# PT32x066xx register map
File version: 0.3
Registers are 32-bit, read-write, reset 0x0 unless marked. A register's access mark holds for its fields unless they carry their own. Offsets are from the block's base; [hi:lo] are bit positions.

## SDADC0 — Segma Delta Analog-to-digital converters
Base 0x40012000
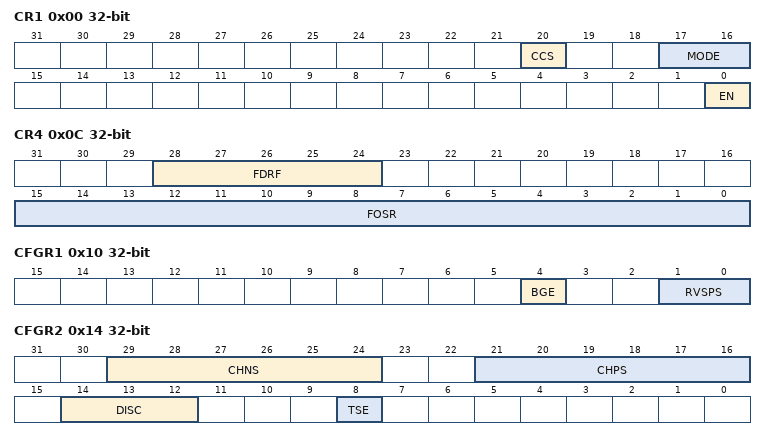
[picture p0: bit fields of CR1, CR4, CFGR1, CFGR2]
0x00 CR1 — Control Register 1
  [20] CCS — Chopper clock source selection
  [17:16] MODE — Working mode
  [0] EN — ADC enable
0x04 CR2 — Control Register 2
  [2] DMAE — SDADC DMA enable
0x0C CR4 — Control Register 4
  [28:24] FDRF — CIC filter data maximum output resolution factor
  [15:0] FOSR — CIC filter oversampling ratio
0x10 CFGR1 — Configuration Register 1
  [4] BGE — BGREF enable
  [1:0] RVSPS — Reference voltage source positive selection
0x14 CFGR2 — Configuration Register 2
  [29:24] CHNS — SDADC channel negative selection
  [21:16] CHPS — SDADC channel positive selection
  [14:12] DISC — Number of conversions to be Discarded
  [8] TSE — Temperature sensor enable
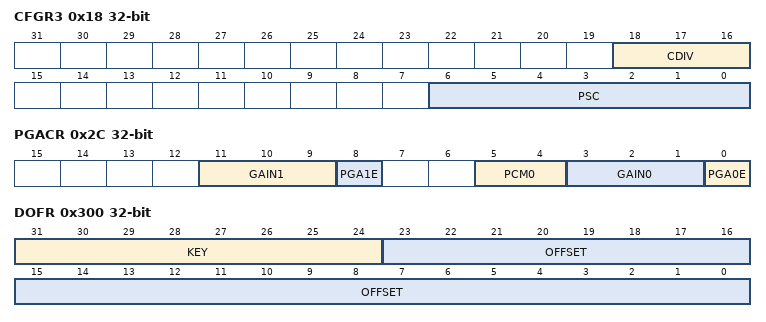
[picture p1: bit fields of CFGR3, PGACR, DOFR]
0x18 CFGR3 — Configuration Register 3
  [18:16] CDIV — Chopper clock divider
  [6:0] PSC — SADC prescaler
0x1C IER — Interrupt Enable Register
  [1] EOCIE — Regular channel end of conversion interrupt enable
0x20 SR ro — Status Register
  [1] EOC — Regular channel end of conversion flag
0x2C PGACR — PGA Control Register
  [11:9] GAIN1 — PGA1 gain value selection
  [8] PGA1E — PGA1 enable
  [5:4] PCM0 — PGA0 chopper working mode selection
  [3:1] GAIN0 — PGA0 gain value selection
  [0] PGA0E — PGA0 enable
0x30 DR ro — Data Register
  [23:0] DATA — SDADC data
0x300 DOFR — Data Offset Register
  [31:24] KEY — Key value
  [23:0] OFFSET — SDADC data offset value
0x304 CCR1 — Common Control Register 1
  [1:0] CHOPE — SDADC chopper enable

## LPTIM — Low Power timer
Base 0x40006C00
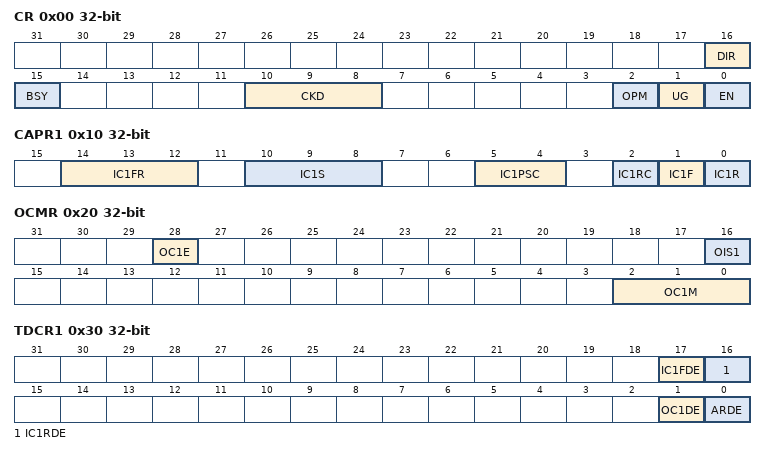
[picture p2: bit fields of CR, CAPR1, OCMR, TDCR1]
0x00 CR access per field — Control Register
  [16] DIR ro — Direction
  [15] BSY ro — Register busy
  [10:8] CKD rw — Sampling clock division
  [2] OPM rw — One-pulse mode
  [1] UG wo — Update generation
  [0] EN rw — TIM enable
0x0C PCR — Polarity Control Register
  [0] CC1P — Capture/Compare 1 output polarity
0x10 CAPR1 — Capture Configuration Register 1
  [14:12] IC1FR — Input capture 1 filter
  [10:8] IC1S — input capture 1 source selection
  [5:4] IC1PSC — Input capture 1 prescaler
  [2] IC1RC — input capture 1 capture reset counter enable
  [1] IC1F — input capture 1 falling capture enable
  [0] IC1R — input capture 1 rising capture enable
0x20 OCMR — Output Compare Mode Register
  [28] OC1E — Compare output 1 output enable
  [16] OIS1 — Output Idle state 1
  [2:0] OC1M — output compare 1 mode
0x30 TDCR1 — Trigger DMA Control Register 1
  [17] IC1FDE — input capture 1 falling edge DMA request enable
  [16] IC1RDE — input capture 1 rising edge DMA request enable
  [1] OC1DE — output compare 1 DMA request enable
  [0] ARDE — auto reload DMA request enable
0x34 TDCR2 — Trigger DMA Control Register 2
  [2] UDE — update DMA request enable
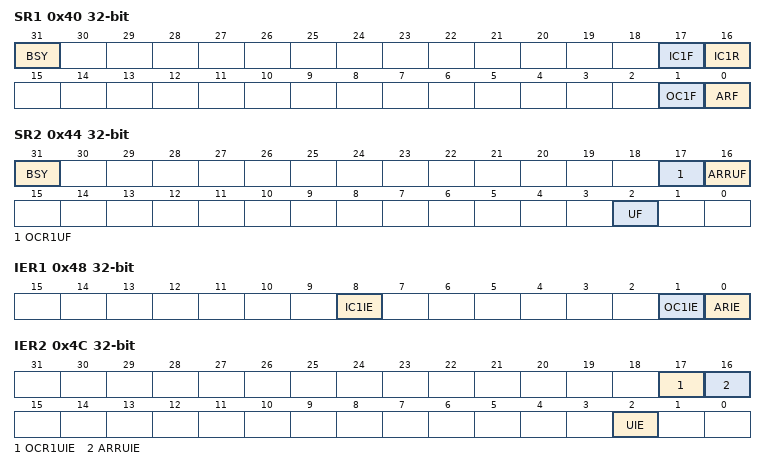
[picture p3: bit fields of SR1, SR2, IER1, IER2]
0x40 SR1 — Status Register 1
  [31] BSY — Register busy
  [17] IC1F — Input capture 1 falling edge
  [16] IC1R — Input capture 1 rising edge
  [1] OC1F — Output compare 1 flag
  [0] ARF — Auto reload flag
0x44 SR2 — Status Register 2
  [31] BSY — Register busy
  [17] OCR1UF — OCR1 update completed flag
  [16] ARRUF — ARR update completed flag
  [2] UF — update flag
0x48 IER1 — Interrupt Enable Register 1
  [8] IC1IE — input capture 1 interrupt enable
  [1] OC1IE — output compare 1 interrupt enable
  [0] ARIE — Auto reload interrupt enable
0x4C IER2 — Interrupt Enable Register 2
  [17] OCR1UIE — OCR1 update completed interrupt enable
  [16] ARRUIE — ARR update completed interrupt enable
  [2] UIE — Update interrupt enable
0x50 ITARR — Interrupt Auto Reload Register
  [7:0] ITARR — TIM interrupt auto reload
0x54 ITCNTR ro — Interrupt Counter Register
  [7:0] ITCNT — TIM interrupt counter value
0x58 PSCR — Prescaler Register
  [15:0] PSC — Prescaler value
0x60 CNTR — Counter Register
  [15:0] CNT — Counter value
0x64 ARR — Auto Reload Register
  [15:0] ARR — Auto reload value
0x68 OCR1 — Output Compare Register 1
  [15:0] OCR — output compare value
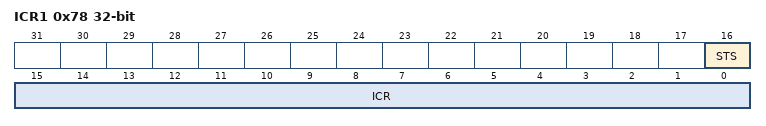
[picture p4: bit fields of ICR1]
0x78 ICR1 ro — Input Capture Register 1
  [16] STS — input capture status
  [15:0] ICR — input capture value
